VERSION ""

NS_ :

BS_:

BU_: AEM Vector__XXX

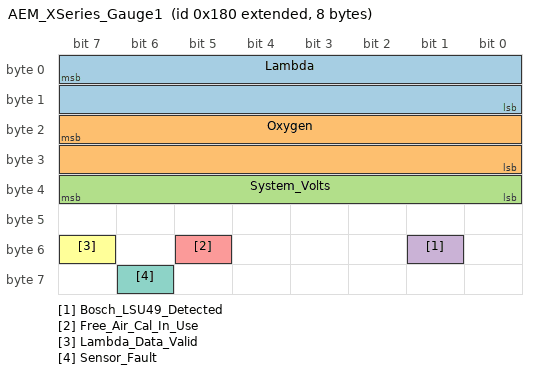
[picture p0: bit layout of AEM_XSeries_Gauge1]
BO_ 2147484032 AEM_XSeries_Gauge1: 8 AEM
 SG_ Lambda : 7|16@0+ (0.0001,0) [0|6.5535] "lambda" Vector__XXX
 SG_ Oxygen : 23|16@0- (0.001,0) [-32.768|32.767] "%" Vector__XXX
 SG_ System_Volts : 39|8@0+ (0.1,0) [0|25.5] "V" Vector__XXX
 SG_ Bosch_LSU49_Detected : 49|1@0+ (1,0) [0|1] "" Vector__XXX
 SG_ Free_Air_Cal_In_Use : 53|1@0+ (1,0) [0|1] "" Vector__XXX
 SG_ Lambda_Data_Valid : 55|1@0+ (1,0) [0|1] "" Vector__XXX
 SG_ Sensor_Fault : 62|1@0+ (1,0) [0|1] "" Vector__XXX

CM_ BO_ 2147484032 "AEM X-Series UEGO gauge AEMnet broadcast (gauge ID1 = 0x180, up to 0x18F). 500 kbit/s, 29-bit extended, big-endian (Motorola), 100 Hz, DLC 8. Decoded from 30-0300 X-Series manual.";
CM_ SG_ 2147484032 Lambda "Wideband lambda. AFR (gasoline) = Lambda * 14.65.";
CM_ SG_ 2147484032 Lambda_Data_Valid "1 = lambda reading valid; gate the value on this.";
CM_ SG_ 2147484032 Sensor_Fault "1 = UEGO sensor fault.";
VAL_ 2147484032 Lambda_Data_Valid 0 "Invalid" 1 "Valid" ;
VAL_ 2147484032 Sensor_Fault 0 "Ok" 1 "Fault" ;
